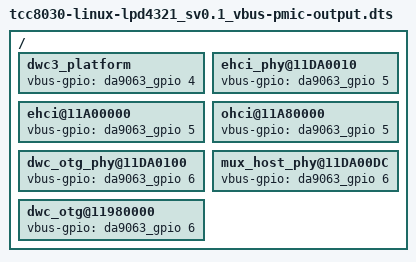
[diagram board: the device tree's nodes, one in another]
/*
 * Device tree for Telechips TCC8031 AVN board
 *
 * Copyright (C) 2018 Telechips Inc. - http://www.telechips.com
 *
 * This file is dual-licensed: you can use it either under the terms
 * of the GPL or the X11 license, at your option. Note that this dual
 * licensing only applies to this file, and not this project as a
 * whole.
 *
 *  a) This file is free software; you can redistribute it and/or
 *     modify it under the terms of the GNU General Public License as
 *     published by the Free Software Foundation; either version 2 of the
 *     License, or (at your option) any later version.
 *
 *     This file is distributed in the hope that it will be useful,
 *     but WITHOUT ANY WARRANTY; without even the implied warranty of
 *     MERCHANTABILITY or FITNESS FOR A PARTICULAR PURPOSE.  See the
 *     GNU General Public License for more details.
 *
 * Or, alternatively,
 *
 *  b) Permission is hereby granted, free of charge, to any person
 *     obtaining a copy of this software and associated documentation
 *     files (the "Software"), to deal in the Software without
 *     restriction, including without limitation the rights to use,
 *     copy, modify, merge, publish, distribute, sublicense, and/or
 *     sell copies of the Software, and to permit persons to whom the
 *     Software is furnished to do so, subject to the following
 *     conditions:
 *
 *     The above copyright notice and this permission notice shall be
 *     included in all copies or substantial portions of the Software.
 *
 *     THE SOFTWARE IS PROVIDED "AS IS", WITHOUT WARRANTY OF ANY KIND,
 *     EXPRESS OR IMPLIED, INCLUDING BUT NOT LIMITED TO THE WARRANTIES
 *     OF MERCHANTABILITY, FITNESS FOR A PARTICULAR PURPOSE AND
 *     NONINFRINGEMENT. IN NO EVENT SHALL THE AUTHORS OR COPYRIGHT
 *     HOLDERS BE LIABLE FOR ANY CLAIM, DAMAGES OR OTHER LIABILITY,
 *     WHETHER IN AN ACTION OF CONTRACT, TORT OR OTHERWISE, ARISING
 *     FROM, OUT OF OR IN CONNECTION WITH THE SOFTWARE OR THE USE OR
 *     OTHER DEALINGS IN THE SOFTWARE.
 */

/dts-v1/;

#include "tcc8030-linux-lpd4321_sv0.1.dts"

/ {
	/* USB 3.0 DRD */                      
	dwc3_platform { 
		vbus-gpio = <&da9063_gpio 4 0>;
	};

	/* USB 2.0 OTG */
	ehci_phy@11DA0010 {
		vbus-gpio = <&da9063_gpio 5 0>;
	};

	ehci@11A00000 {
		vbus-gpio = <&da9063_gpio 5 0>;
	};

	ohci@11A80000 {
		vbus-gpio = <&da9063_gpio 5 0>;
	};

	dwc_otg_phy@11DA0100 {
		vbus-gpio = <&da9063_gpio 6 0>;
	};

	mux_host_phy@11DA00DC {
		vbus-gpio = <&da9063_gpio 6 0>;
	};

	dwc_otg@11980000 {
	    vbus-gpio = <&da9063_gpio 6 0>;
	};


};
